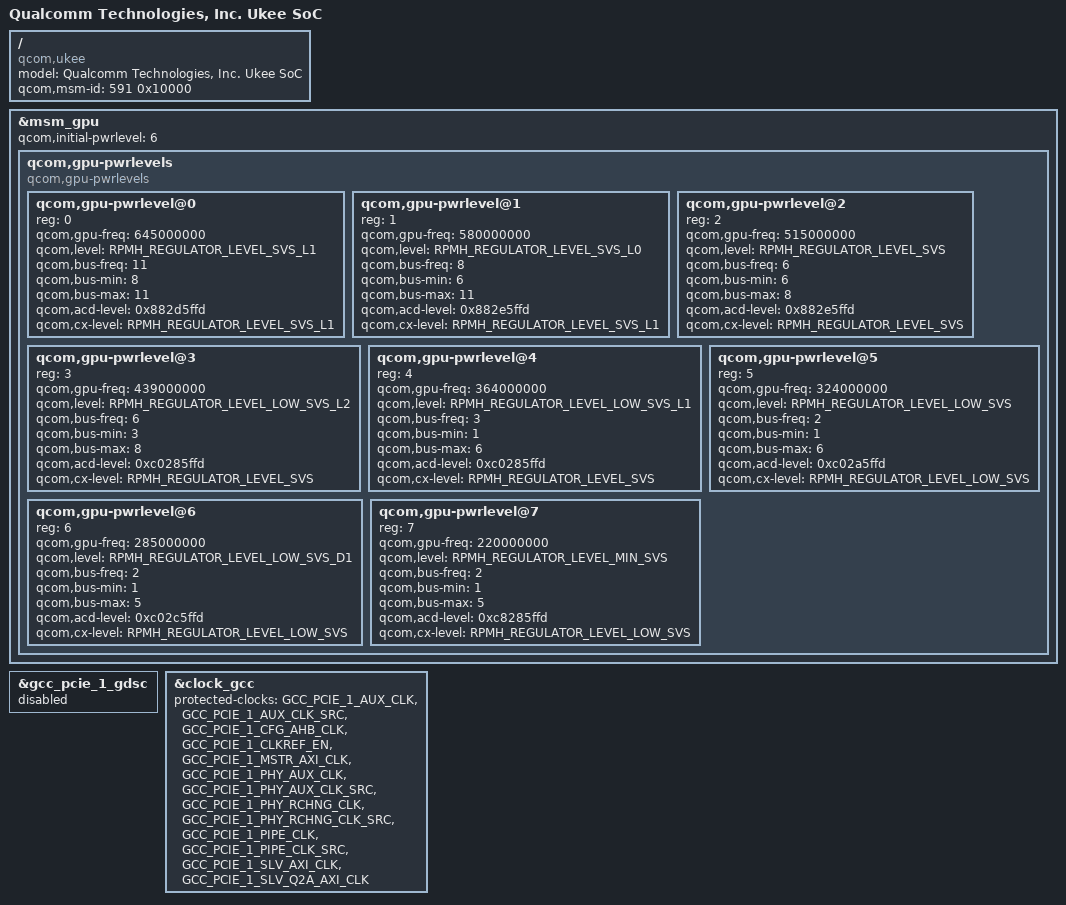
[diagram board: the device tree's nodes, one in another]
#include "cape.dtsi"

/ {
	model = "Qualcomm Technologies, Inc. Ukee SoC";
	compatible = "qcom,ukee";
	qcom,msm-id = <591 0x10000>;
};

&msm_gpu {
	qcom,initial-pwrlevel = <6>;

	/delete-node/qcom,gpu-pwrlevels;

	/* Power levels */
	qcom,gpu-pwrlevels {
		#address-cells = <1>;
		#size-cells = <0>;

		compatible = "qcom,gpu-pwrlevels";

		qcom,gpu-pwrlevel@0 {
			reg = <0>;
			qcom,gpu-freq = <645000000>;
			qcom,level = <RPMH_REGULATOR_LEVEL_SVS_L1>;

			qcom,bus-freq = <11>;
			qcom,bus-min = <8>;
			qcom,bus-max = <11>;

			qcom,acd-level = <0x882d5ffd>;
			qcom,cx-level = <RPMH_REGULATOR_LEVEL_SVS_L1>;
		};

		qcom,gpu-pwrlevel@1 {
			reg = <1>;
			qcom,gpu-freq = <580000000>;
			qcom,level = <RPMH_REGULATOR_LEVEL_SVS_L0>;

			qcom,bus-freq = <8>;
			qcom,bus-min = <6>;
			qcom,bus-max = <11>;

			qcom,acd-level = <0x882e5ffd>;
			qcom,cx-level = <RPMH_REGULATOR_LEVEL_SVS_L1>;
		};

		qcom,gpu-pwrlevel@2 {
			reg = <2>;
			qcom,gpu-freq = <515000000>;
			qcom,level = <RPMH_REGULATOR_LEVEL_SVS>;

			qcom,bus-freq = <6>;
			qcom,bus-min = <6>;
			qcom,bus-max = <8>;

			qcom,acd-level = <0x882e5ffd>;
			qcom,cx-level = <RPMH_REGULATOR_LEVEL_SVS>;
		};

		qcom,gpu-pwrlevel@3 {
			reg = <3>;
			qcom,gpu-freq = <439000000>;
			qcom,level = <RPMH_REGULATOR_LEVEL_LOW_SVS_L2>;

			qcom,bus-freq = <6>;
			qcom,bus-min = <3>;
			qcom,bus-max = <8>;

			qcom,acd-level = <0xc0285ffd>;
			qcom,cx-level = <RPMH_REGULATOR_LEVEL_SVS>;
		};

		qcom,gpu-pwrlevel@4 {
			reg = <4>;
			qcom,gpu-freq = <364000000>;
			qcom,level = <RPMH_REGULATOR_LEVEL_LOW_SVS_L1>;

			qcom,bus-freq = <3>;
			qcom,bus-min = <1>;
			qcom,bus-max = <6>;

			qcom,acd-level = <0xc0285ffd>;
			qcom,cx-level = <RPMH_REGULATOR_LEVEL_SVS>;
		};

		qcom,gpu-pwrlevel@5 {
			reg = <5>;
			qcom,gpu-freq = <324000000>;
			qcom,level = <RPMH_REGULATOR_LEVEL_LOW_SVS>;

			qcom,bus-freq = <2>;
			qcom,bus-min = <1>;
			qcom,bus-max = <6>;

			qcom,acd-level = <0xc02a5ffd>;

			qcom,cx-level = <RPMH_REGULATOR_LEVEL_LOW_SVS>;
		};

		qcom,gpu-pwrlevel@6 {
			reg = <6>;
			qcom,gpu-freq = <285000000>;
			qcom,level = <RPMH_REGULATOR_LEVEL_LOW_SVS_D1>;

			qcom,bus-freq = <2>;
			qcom,bus-min = <1>;
			qcom,bus-max = <5>;

			qcom,acd-level = <0xc02c5ffd>;

			qcom,cx-level = <RPMH_REGULATOR_LEVEL_LOW_SVS>;
		};

		qcom,gpu-pwrlevel@7 {
			reg = <7>;
			qcom,gpu-freq = <220000000>;
			qcom,level = <RPMH_REGULATOR_LEVEL_MIN_SVS>;

			qcom,bus-freq = <2>;
			qcom,bus-min = <1>;
			qcom,bus-max = <5>;

			qcom,acd-level = <0xc8285ffd>;

			qcom,cx-level = <RPMH_REGULATOR_LEVEL_LOW_SVS>;
		};
	};
};

&gcc_pcie_1_gdsc {
	status =  "disabled";
};

&clock_gcc {
	protected-clocks = <GCC_PCIE_1_AUX_CLK>, <GCC_PCIE_1_AUX_CLK_SRC>,
			<GCC_PCIE_1_CFG_AHB_CLK>, <GCC_PCIE_1_CLKREF_EN>,
			<GCC_PCIE_1_MSTR_AXI_CLK>, <GCC_PCIE_1_PHY_AUX_CLK>,
			<GCC_PCIE_1_PHY_AUX_CLK_SRC>, <GCC_PCIE_1_PHY_RCHNG_CLK>,
			<GCC_PCIE_1_PHY_RCHNG_CLK_SRC>, <GCC_PCIE_1_PIPE_CLK>,
			<GCC_PCIE_1_PIPE_CLK_SRC>, <GCC_PCIE_1_SLV_AXI_CLK>,
			<GCC_PCIE_1_SLV_Q2A_AXI_CLK>;
};
